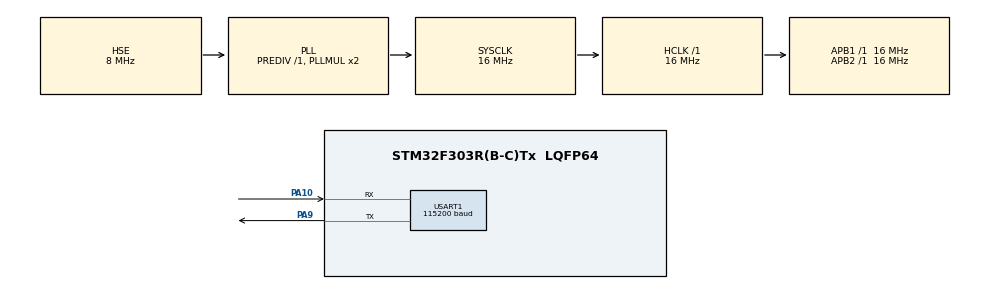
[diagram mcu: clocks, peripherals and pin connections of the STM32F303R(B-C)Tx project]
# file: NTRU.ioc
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Mcu.Family=STM32F3
Mcu.Name=STM32F303R(B-C)Tx
Mcu.Package=LQFP64
NVIC.PriorityGroup=NVIC_PRIORITYGROUP_4
PA10.Mode=Asynchronous
PA10.Signal=USART1_RX
PA9.Mode=Asynchronous
PA9.Signal=USART1_TX
PF0-OSC_IN.Mode=HSE-External-Oscillator
PF0-OSC_IN.Signal=RCC_OSC_IN
PF1-OSC_OUT.Mode=HSE-External-Oscillator
PF1-OSC_OUT.Signal=RCC_OSC_OUT
ProjectManager.HeapSize=0x200
ProjectManager.StackSize=0x400
ProjectManager.TargetToolchain=STM32CubeIDE
RCC.AHBFreq_Value=16000000
RCC.APB1Freq_Value=16000000
RCC.APB1TimFreq_Value=16000000
RCC.APB2Freq_Value=16000000
RCC.APB2TimFreq_Value=16000000
RCC.CortexFreq_Value=16000000
RCC.HCLKFreq_Value=16000000
RCC.HSE_VALUE=8000000
RCC.HSI_VALUE=8000000
RCC.LSE_VALUE=32768
RCC.PLLSourceVirtual=RCC_PLLSOURCE_HSE
RCC.SYSCLKFreq_VALUE=16000000
RCC.SYSCLKSourceVirtual=RCC_SYSCLKSOURCE_PLLCLK
RCC.USBFreq_Value=16000000
USART1.BaudRate=115200
USART1.VirtualMode-Asynchronous=VM_ASYNC
board=custom

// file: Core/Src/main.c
/* USER CODE BEGIN Header */
/**
  ******************************************************************************
  * @file           : main.c
  * @brief          : Main program body
  ******************************************************************************
  * @attention
  *
  * Copyright (c) 2024 STMicroelectronics.
  * All rights reserved.
  *
  * This software is licensed under terms that can be found in the LICENSE file
  * in the root directory of this software component.
  * If no LICENSE file comes with this software, it is provided AS-IS.
  *
  ******************************************************************************
  */
/* USER CODE END Header */
#include "main.h"

/* USER CODE BEGIN Includes */
#include "test.h"
#define MLEN 16
/* USER CODE END Includes */

UART_HandleTypeDef huart1;

void SystemClock_Config(void);
static void MX_GPIO_Init(void);
static void MX_USART1_UART_Init(void);

int main(void)
{

  /* USER CODE BEGIN 1 */
	uint8_t public_key[557];          /* sized for EES401EP2 */
	uint16_t public_key_len;          /* no. of octets in public key */
	uint8_t private_key[607];         /* sized for EES401EP2 */
	uint16_t private_key_len;         /* no. of octets in private key */
	uint8_t encoded_public_key[593];  /* sized for EES401EP2 */
	uint16_t encoded_public_key_len;  /* no. of octets in encoded public key */
	uint8_t ciphertext[552];          /* sized fof EES401EP2 */
	uint16_t ciphertext_len;          /* no. of octets in ciphertext */
	uint8_t *next = NULL;             /* points to next cert field to parse */
	uint32_t next_len;                /* no. of octets it next */
	DRBG_HANDLE drbg;                 /* handle for instantiated DRBG */
	uint16_t plaintext_len;           /* no. of octets in plaintext */
	uint8_t ok[4] = {0x74, 0x72, 0x75, 0x65};

	/* Personalization string to be used for DRBG instantiation.*/
	static uint8_t const pers_str[] = {'S', 'S', 'L', ' ', 'a', 'p', 'p', 'l', 'i', 'c', 'a', 't', 'i', 'o', 'n'};

	/* AES-128 key to be encrypted. */
	static uint8_t m[MLEN];
	int vry = 0;
	int ret = 0;
  /* USER CODE END 1 */

  /* MCU Configuration--------------------------------------------------------*/

  /* Reset of all peripherals, Initializes the Flash interface and the Systick. */
  HAL_Init();

  /* Configure the system clock */
  SystemClock_Config();

  /* Initialize all configured peripherals */
  MX_GPIO_Init();
  MX_USART1_UART_Init();
  /* USER CODE BEGIN 2 */
  ntru_crypto_drbg_instantiate(112, pers_str, sizeof(pers_str), (ENTROPY_FN) &get_entropy, &drbg);
  ntru_crypto_ntru_encrypt_keygen(drbg, NTRU_EES401EP2, &public_key_len, public_key, &private_key_len, private_key);
  ntru_crypto_drbg_uninstantiate(drbg);

  ntru_crypto_ntru_encrypt_publicKey2SubjectPublicKeyInfo(public_key_len, public_key, &encoded_public_key_len, encoded_public_key);

  next = encoded_public_key;
  next_len = encoded_public_key_len;

  ntru_crypto_ntru_encrypt_subjectPublicKeyInfo2PublicKey(next, &public_key_len, public_key, &next, &next_len);

  ntru_crypto_drbg_instantiate(112, NULL, 0, (ENTROPY_FN)&get_entropy, &drbg);
  /* USER CODE END 2 */

  /* Infinite loop */
  /* USER CODE BEGIN WHILE */
  while (1)
  {
	  ret = HAL_UART_Receive(&huart1, m, MLEN, HAL_MAX_DELAY);
	  if(ret==HAL_OK)
	  {
		  __disable_irq();  // disable interrupts
		  HAL_GPIO_WritePin(GPIOA, GPIO_PIN_6, 1); // drive the level high before the operation as a trigger signal
		  ntru_crypto_ntru_encrypt(drbg, public_key_len, public_key, MLEN, m, &ciphertext_len, ciphertext);
		  HAL_GPIO_WritePin(GPIOA, GPIO_PIN_6, 0); // drive the level low after the operation
		  __enable_irq();  // enable interrupts
		  HAL_UART_Transmit(&huart1, ciphertext, ciphertext_len, HAL_MAX_DELAY);

		  __disable_irq();  // disable interrupts
	   	  HAL_GPIO_WritePin(GPIOA, GPIO_PIN_6, 1); // drive the level high before the operation as a trigger signal
	   	  vry = ntru_crypto_ntru_decrypt(private_key_len, private_key, ciphertext_len, ciphertext, &plaintext_len, m);
	   	  HAL_GPIO_WritePin(GPIOA, GPIO_PIN_6, 0); // drive the level low after the operation
	   	  __enable_irq();  // enable interrupts
	   	  if (vry == 0) {  // signature verification succeeded
	   	    HAL_UART_Transmit(&huart1, ok, 4, HAL_MAX_DELAY);
	   	  }
	   }
    /* USER CODE END WHILE */

  }
}

void SystemClock_Config(void)
{
  RCC_OscInitTypeDef RCC_OscInitStruct = {0};
  RCC_ClkInitTypeDef RCC_ClkInitStruct = {0};
  RCC_PeriphCLKInitTypeDef PeriphClkInit = {0};

  /** Initializes the RCC Oscillators according to the specified parameters
  * in the RCC_OscInitTypeDef structure.
  */
  RCC_OscInitStruct.OscillatorType = RCC_OSCILLATORTYPE_HSE;
  RCC_OscInitStruct.HSEState = RCC_HSE_ON;
  RCC_OscInitStruct.HSEPredivValue = RCC_HSE_PREDIV_DIV1;
  RCC_OscInitStruct.HSIState = RCC_HSI_ON;
  RCC_OscInitStruct.PLL.PLLState = RCC_PLL_ON;
  RCC_OscInitStruct.PLL.PLLSource = RCC_PLLSOURCE_HSE;
  RCC_OscInitStruct.PLL.PLLMUL = RCC_PLL_MUL2;
  if (HAL_RCC_OscConfig(&RCC_OscInitStruct) != HAL_OK)
  {
    Error_Handler();
  }

  /** Initializes the CPU, AHB and APB buses clocks
  */
  RCC_ClkInitStruct.ClockType = RCC_CLOCKTYPE_HCLK|RCC_CLOCKTYPE_SYSCLK
                              |RCC_CLOCKTYPE_PCLK1|RCC_CLOCKTYPE_PCLK2;
  RCC_ClkInitStruct.SYSCLKSource = RCC_SYSCLKSOURCE_PLLCLK;
  RCC_ClkInitStruct.AHBCLKDivider = RCC_SYSCLK_DIV1;
  RCC_ClkInitStruct.APB1CLKDivider = RCC_HCLK_DIV1;
  RCC_ClkInitStruct.APB2CLKDivider = RCC_HCLK_DIV1;

  if (HAL_RCC_ClockConfig(&RCC_ClkInitStruct, FLASH_LATENCY_0) != HAL_OK)
  {
    Error_Handler();
  }
  PeriphClkInit.PeriphClockSelection = RCC_PERIPHCLK_USART1;
  PeriphClkInit.Usart1ClockSelection = RCC_USART1CLKSOURCE_PCLK2;
  if (HAL_RCCEx_PeriphCLKConfig(&PeriphClkInit) != HAL_OK)
  {
    Error_Handler();
  }
}

static void MX_USART1_UART_Init(void)
{

  huart1.Instance = USART1;
  huart1.Init.BaudRate = 115200;
  huart1.Init.WordLength = UART_WORDLENGTH_8B;
  huart1.Init.StopBits = UART_STOPBITS_1;
  huart1.Init.Parity = UART_PARITY_NONE;
  huart1.Init.Mode = UART_MODE_TX_RX;
  huart1.Init.HwFlowCtl = UART_HWCONTROL_NONE;
  huart1.Init.OverSampling = UART_OVERSAMPLING_16;
  huart1.Init.OneBitSampling = UART_ONE_BIT_SAMPLE_DISABLE;
  huart1.AdvancedInit.AdvFeatureInit = UART_ADVFEATURE_NO_INIT;
  if (HAL_UART_Init(&huart1) != HAL_OK)
  {
    Error_Handler();
  }

}

static void MX_GPIO_Init(void)
{

  /* GPIO Ports Clock Enable */
  __HAL_RCC_GPIOF_CLK_ENABLE();
  __HAL_RCC_GPIOA_CLK_ENABLE();

}

void Error_Handler(void)
{
  __disable_irq();
  while (1)
  {
  }
}
